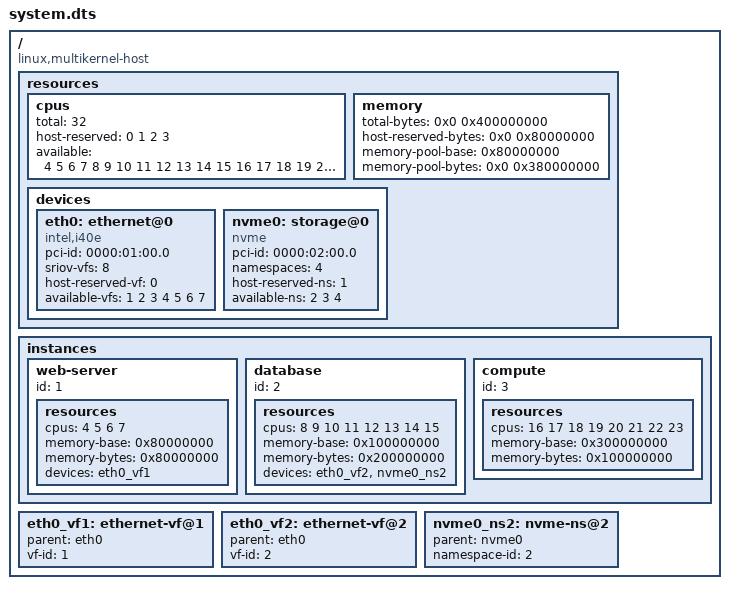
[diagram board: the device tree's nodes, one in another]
/multikernel-v1/;

/ {
    compatible = "linux,multikernel-host";
    
    // ========== MAPS TO /sys/kernel/multikernel/device_tree ==========
    resources {
        cpus {
            total = <32>;
            host-reserved = <0 1 2 3>;
            available = <4 5 6 7 8 9 10 11 12 13 14 15 
                        16 17 18 19 20 21 22 23 24 25 26 27 28 29 30 31>;
        };
        
        memory {
            total-bytes = <0x0 0x400000000>;      // 16GB
            host-reserved-bytes = <0x0 0x80000000>; // 2GB
            memory-pool-base = <0x80000000>;
            memory-pool-bytes = <0x0 0x380000000>;  // 14GB
        };
        
        devices {
            eth0: ethernet@0 {
                compatible = "intel,i40e";
                pci-id = "0000:01:00.0";
                sriov-vfs = <8>;
                host-reserved-vf = <0>;
                available-vfs = <1 2 3 4 5 6 7>;
            };
            
            nvme0: storage@0 {
                compatible = "nvme";
                pci-id = "0000:02:00.0";
                namespaces = <4>;
                host-reserved-ns = <1>;
                available-ns = <2 3 4>;
            };
        };
    };
    
    // ========== MAPS TO /sys/kernel/multikernel/instances/ ==========
    instances {
        // Maps to /sys/kernel/multikernel/instances/web-server/
        web-server {
            id = <1>;
            
            resources {
                cpus = <4 5 6 7>;
                memory-base = <0x80000000>;
                memory-bytes = <0x80000000>;  // 2GB
                devices = <&eth0_vf1>;
            };
            
        };
        
        // Maps to /sys/kernel/multikernel/instances/database/
        database {
            id = <2>;
            
            resources {
                cpus = <8 9 10 11 12 13 14 15>;
                memory-base = <0x100000000>;
                memory-bytes = <0x200000000>;  // 8GB
                devices = <&eth0_vf2>, <&nvme0_ns2>;
            };
            
        };
        
        // Maps to /sys/kernel/multikernel/instances/compute/
        compute {
            id = <3>;
            
            resources {
                cpus = <16 17 18 19 20 21 22 23>;
                memory-base = <0x300000000>;
                memory-bytes = <0x100000000>;  // 4GB
            };
            
        };
    };
    
    // ========== DEVICE REFERENCES (phandle targets) ==========
    eth0_vf1: ethernet-vf@1 {
        parent = <&eth0>;
        vf-id = <1>;
    };
    
    eth0_vf2: ethernet-vf@2 {
        parent = <&eth0>;
        vf-id = <2>;
    };
    
    nvme0_ns2: nvme-ns@2 {
        parent = <&nvme0>;
        namespace-id = <2>;
    };
};
